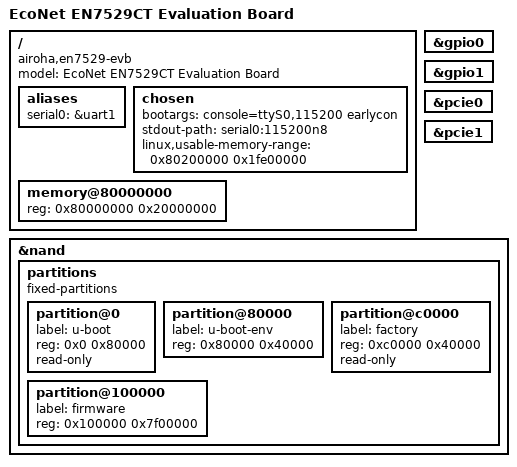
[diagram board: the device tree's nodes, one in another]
// SPDX-License-Identifier: (GPL-2.0-only OR BSD-2-Clause)
/dts-v1/;


/memreserve/ 0x80000000 0x200000;

#include "en7529.dtsi"

/ {
	model = "EcoNet EN7529CT Evaluation Board";
	compatible = "airoha,en7529-evb", "airoha,en7529";
	aliases {
		serial0 = &uart1;
	};

	chosen {
		bootargs = "console=ttyS0,115200 earlycon";
		stdout-path = "serial0:115200n8";
		linux,usable-memory-range = <0x80200000 0x1fe00000>;
	};

	memory@80000000 {
		device_type = "memory";
		reg = <0x80000000 0x20000000>; 
	};
};

&gpio0 {
	status = "okay";
};

&gpio1 {
	status = "okay";
};

&pcie0 {
	status = "okay";
};

&pcie1 {
	status = "okay";
};

&nand {
	status = "okay";

	partitions {
		compatible = "fixed-partitions";
		#address-cells = <1>;
		#size-cells = <1>;

		partition@0 {
			label = "u-boot";
			reg = <0x0 0x80000>;
			read-only;
		};

		partition@80000 {
			label = "u-boot-env";
			reg = <0x80000 0x40000>;
		};

		partition@c0000 {
			label = "factory";
			reg = <0xc0000 0x40000>;
			read-only;
		};

		partition@100000 {
			label = "firmware";
			reg = <0x100000 0x7f00000>;
		};
	};
};
